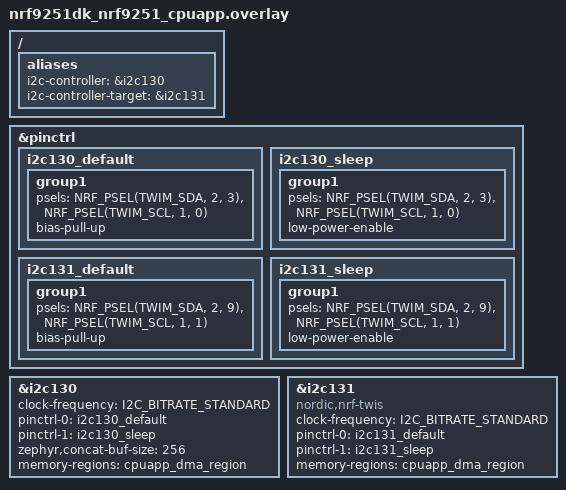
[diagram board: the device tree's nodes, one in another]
/*
 * Copyright (c) 2026 Nordic Semiconductor ASA
 *
 * SPDX-License-Identifier: LicenseRef-Nordic-5-Clause
 */

/*
 * SDA = P2.3 and P2.9
 * SCL = P1.0 and P1.1
 */

/ {
	aliases {
		i2c-controller = &i2c130;
		i2c-controller-target = &i2c131;
	};
};

&pinctrl {
	i2c130_default: i2c130_default {
		group1 {
			psels = <NRF_PSEL(TWIM_SDA, 2, 3)>,
				<NRF_PSEL(TWIM_SCL, 1, 0)>;
			bias-pull-up;
		};
	};

	i2c130_sleep: i2c130_sleep {
		group1 {
			psels = <NRF_PSEL(TWIM_SDA, 2, 3)>,
				<NRF_PSEL(TWIM_SCL, 1, 0)>;
			low-power-enable;
		};
	};

	i2c131_default: i2c131_default {
		group1 {
			psels = <NRF_PSEL(TWIM_SDA, 2, 9)>,
				<NRF_PSEL(TWIM_SCL, 1, 1)>;
			bias-pull-up;
		};
	};

	i2c131_sleep: i2c131_sleep {
		group1 {
			psels = <NRF_PSEL(TWIM_SDA, 2, 9)>,
				<NRF_PSEL(TWIM_SCL, 1, 1)>;
			low-power-enable;
		};
	};
};

&i2c130 {
	clock-frequency = <I2C_BITRATE_STANDARD>;
	pinctrl-0 = <&i2c130_default>;
	pinctrl-1 = <&i2c130_sleep>;
	pinctrl-names = "default", "sleep";
	zephyr,concat-buf-size = <256>;
	memory-regions = <&cpuapp_dma_region>;
	status = "okay";
};

&i2c131 {
	compatible = "nordic,nrf-twis";
	clock-frequency = <I2C_BITRATE_STANDARD>;
	pinctrl-0 = <&i2c131_default>;
	pinctrl-1 = <&i2c131_sleep>;
	pinctrl-names = "default", "sleep";
	memory-regions = <&cpuapp_dma_region>;
	status = "okay";
};
